# FPU_356.0 register map
Vendor: Texas Instruments
Peripheral module from a debugger description file (folder MSP432).
Registers are 32-bit, read-write, no defined reset value unless marked. A register's access mark holds for its fields unless they carry their own. Offsets are as the file gives them; lines under a group give offsets from that group; [hi:lo] are bit positions; {n}, {i} and the like mark numbered series; 'fields as' and 'values as' point back to an identical list; <NAME> marks a mode.

## FPU
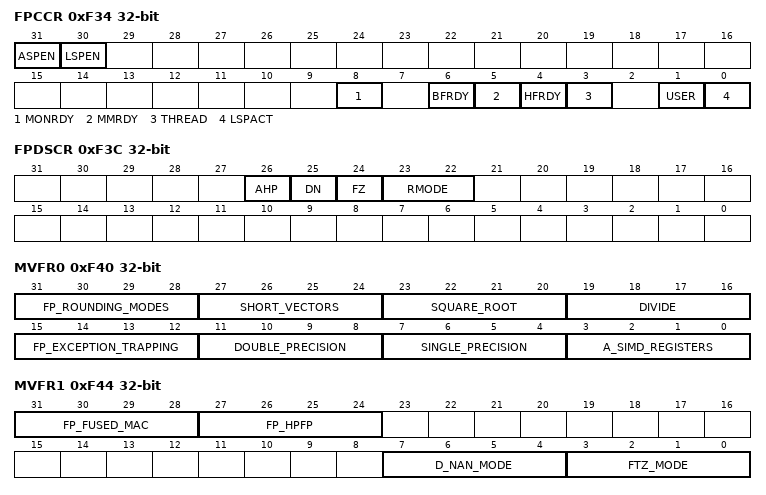
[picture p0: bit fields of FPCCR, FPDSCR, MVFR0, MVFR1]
0xF34 FPCCR — Floating Point Context Control Register
  [31] ASPEN — Automatic State Preservation ENable. When this bit is set is will cause bit [2] of the Special CONTROL register to be set (FPCA) on execution of a floating point instruction which results in the floating point state automatically being preserved on exception entry.
  [30] LSPEN — Lazy State Preservation ENable. When the processor performs a context save, space on the stack is reserved for the floating point state but it is not stacked until the new context performs a floating point operation.
  [8] MONRDY — Indicates whether the the software executing when the processor allocated the FP stack frame was able to set the DebugMonitor exception to pending.
  [6] BFRDY — Indicates whether the software executing when the processor allocated the FP stack frame was able to set the BusFault exception to pending.
  [5] MMRDY — Indicates whether the software executing when the processor allocated the FP stack frame was able to set the MemManage exception to pending.
  [4] HFRDY — Indicates whether the software executing when the processor allocated the FP stack frame was able to set the HardFault exception to pending.
  [3] THREAD — Indicates the processor mode was Thread when it allocated the FP stack frame.
  [1] USER — Indicates the privilege level of the software executing was User (Unpriviledged) when the processor allocated the FP stack frame.
  [0] LSPACT — Indicates whether Lazy preservation of the FP state is active.
0xF38 FPCAR — Floating-Point Context Address Register
  [30:2] ADDRESS — Holds the (double-word-aligned) location of the unpopulated floating-point register space allocated on an exception stack frame.
0xF3C FPDSCR — Floating Point Default Status Control Register
  [26] AHP — Default value for Alternative Half Precision bit. (If this bit is set to 1 then Alternative half-precision format is selected).
  [25] DN — Default value for Default NaN mode bit. (If this bit is set to 1 then any operation involving one or more NaNs returns the Default NaN).
  [24] FZ — Default value for Flush-to-Zero mode bit. (If this bit is set to 1 then Flush-to-zero mode is enabled).
  [23:22] RMODE — Default value for Rounding Mode control field. (The encoding for this field is: 0b00 Round to Nearest (RN) mode, 0b01 Round towards Plus Infinity (RP) mode, 0b10 Round towards Minus Infinity (RM) mode, 0b11 Round towards Zero (RZ) mode. The specified rounding mode is used by almost all floating-point instructions).
0xF40 MVFR0 ro — Media and FP Feature Register 0 (MVFR0)
  [31:28] FP_ROUNDING_MODES — Indicates the rounding modes supported by the FP floating-point hardware. The value of this field is: 0b0001 - all rounding modes supported.
  [27:24] SHORT_VECTORS — Indicates the hardware support for FP short vectors. The value of this field is: 0b0000 - not supported in ARMv7-M.
  [23:20] SQUARE_ROOT — Indicates the hardware support for FP square root operations. The value of this field is: 0b0001 - supported.
  [19:16] DIVIDE — Indicates the hardware support for FP divide operations. The value of this field is: 0b0001 - supported.
  [15:12] FP_EXCEPTION_TRAPPING — Indicates whether the FP hardware implementation supports exception trapping. The value of this field is: 0b0000 - not supported in ARMv7-M.
  [11:8] DOUBLE_PRECISION — Indicates the hardware support for FP double-precision operations. The value of this field is: 0b0000 - not supported in ARMv7-M.
  [7:4] SINGLE_PRECISION — Indicates the hardware support for FP single-precision operations. The value of this field is: 0b0010 - supported.
  [3:0] A_SIMD_REGISTERS — Indicates the size of the FP register bank. The value of this field is: 0b0001 - supported, 16 x 64-bit registers.
0xF44 MVFR1 ro — Media and FP Feature Register 1 (MVFR1)
  [31:28] FP_FUSED_MAC — Indicates whether the FP supports fused multiply accumulate operations. The value of this field is: 0b0001 - supported.
  [27:24] FP_HPFP — Indicates whether the FP supports half-precision floating-point conversion operations. The value of this field is: 0b0001 - supported.
  [7:4] D_NAN_MODE — Indicates whether the FP hardware implementation supports only the Default NaN mode. The value of this field is: 0b0001 - hardware supports propagation of NaN values.
  [3:0] FTZ_MODE — Indicates whether the FP hardware implementation supports only the Flush-to-Zero mode of operation. The value of this field is: 0b0001 - hardware supports full denormalized number arithmetic.
